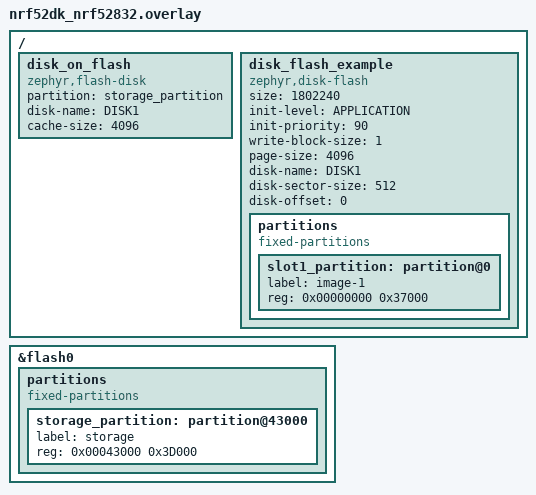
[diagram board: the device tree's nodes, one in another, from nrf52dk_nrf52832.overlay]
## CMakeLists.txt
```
# SPDX-License-Identifier: Apache-2.0

cmake_minimum_required(VERSION 3.20.0)
find_package(Zephyr REQUIRED HINTS $ENV{ZEPHYR_BASE})
project(flash_disk)

option(IMAGE_SECONDARY "Builds the secondary image" OFF)

zephyr_library_include_directories(${ZEPHYR_BASE}/drivers/flash)

if(IMAGE_SECONDARY)
FILE(GLOB app_sources src/secondary.c)
else()
FILE(GLOB app_sources src/main.c)
endif()

target_sources(app PRIVATE ${app_sources})

set(SECONDARY_IMAGE_HEX ${CMAKE_CURRENT_SOURCE_DIR}/generated/secondary.hex)
if(IMAGE_SECONDARY)
message("Secondary image")
set(ZEPHYR_OUTPUT_HEX ${CMAKE_CURRENT_BINARY_DIR}/zephyr/${KERNEL_HEX_NAME})
add_custom_command(
    COMMAND ${CMAKE_COMMAND} -E copy ${ZEPHYR_OUTPUT_HEX} ${SECONDARY_IMAGE_HEX}
    OUTPUT  ${SECONDARY_IMAGE_HEX}
    DEPENDS ${ZEPHYR_OUTPUT_HEX}
    COMMENT "Running post-build copying step..."
)
add_custom_target(
    post_bin ALL
    DEPENDS ${SECONDARY_IMAGE_HEX}
)
else()
set(gen_dir ${ZEPHYR_BINARY_DIR}/include/generated/)
generate_inc_file_for_target(app ${SECONDARY_IMAGE_HEX} ${gen_dir}/secondary.inc)
endif()
```

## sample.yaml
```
sample:
  name: Disk Flash Sample
tests:
  sample.drivers.flash_disk:
    tags:
    - flash
    filter: CONFIG_FLASH_HAS_DRIVER_ENABLED
    harness: console
    harness_config:
      type: one_line
      regex:
      - ".*Read/Write test successful"
```

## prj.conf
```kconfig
CONFIG_FLASH=y
CONFIG_MPU_ALLOW_FLASH_WRITE=y
CONFIG_MINIMAL_LIBC=y

# Enable flash on disk
CONFIG_FLASH_DRIVER_DISK=y

# Enable disk on flash
CONFIG_DISK_ACCESS=y
CONFIG_DISK_DRIVERS=y
#CONFIG_DISK_DRIVER_FLASH=y


# Logging
CONFIG_LOG=y
CONFIG_LOG_DEFAULT_LEVEL=4

# Config dfu
CONFIG_STREAM_FLASH=y
CONFIG_FLASH_MAP=y
CONFIG_IMG_MANAGER=y
CONFIG_MCUBOOT_IMG_MANAGER=y
CONFIG_IMG_ERASE_PROGRESSIVELY=y
CONFIG_REBOOT=y
CONFIG_BOOTLOADER_MCUBOOT=y
```

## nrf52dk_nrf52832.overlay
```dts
/*
 * Copyright (c) 2022-2023 Nordic Semiconductor ASA
 *
 * SPDX-License-Identifier: Apache-2.0
 */

/delete-node/ &slot1_partition;
/delete-node/ &storage_partition;

&flash0 {
	partitions {
		compatible = "fixed-partitions";
		#address-cells = <1>;
		#size-cells = <1>;

		storage_partition: partition@43000 {
			label = "storage";
			reg = <0x00043000 0x3D000>;
		};
	};
};
 
 ///delete-node/ &slot1_partition;
 
 / { 
	disk_on_flash: disk_on_flash {
		compatible = "zephyr,flash-disk";
		status = "okay";
		partition = < &storage_partition >;
		disk-name = "DISK1";
		cache-size = <4096>;
 	};
	disk_flash_example: disk_flash_example {
		compatible = "zephyr,disk-flash";
		status = "okay";
		size = <1802240>;
		init-level = "APPLICATION";
		init-priority = <90>;
		write-block-size = <1>;
		page-size = <4096>;
		disk-name = "DISK1";
		disk-sector-size = <512>;
		disk-offset = <0>;

		partitions {
			compatible = "fixed-partitions";
			#address-cells = <1>;
			#size-cells = <1>;

			slot1_partition: partition@0 {
				label = "image-1";
				reg = <0x00000000 0x37000>;
			};
		};
	};
};
```

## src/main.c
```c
/*
 * Copyright (c) 2023 Endress+Hauser AG
 *
 * SPDX-License-Identifier: Apache-2.0
 */

#include <zephyr/kernel.h>
#include <zephyr/device.h>
#include <zephyr/drivers/flash.h>
#include <zephyr/dfu/mcuboot.h>
#include <zephyr/dfu/flash_img.h>
#include <zephyr/logging/log.h>

// #if DT_HAS_COMPAT_STATUS_OKAY(zephyr_disk_flash)
// #define FLASH_NODE DT_COMPAT_GET_ANY_STATUS_OKAY(zephyr_disk_flash)
// #else
// #error Unsupported flash driver
// #define FLASH_NODE DT_INVALID_NODE
// #endif

LOG_MODULE_REGISTER(main, CONFIG_LOG_DEFAULT_LEVEL);

// static char const secondary[] = {
// #include "secondary.inc"
// };

int main(void)
{
	int res = -1;
	//const struct device *const slot1_dev = DEVICE_DT_GET(FLASH_NODE);
	//uint16_t const image_size = (uint16_t)sizeof(secondary);
	uint16_t bytes_written = 0;
	// k_msleep(3000);

	// if(!boot_is_img_confirmed()) {
	// 	LOG_INF("Confirming image");
	// } else {
	// 	LOG_INF("Image already confirmed");
	// }

	//LOG_INF("Secondary image starts with: %x", secondary[5]);
	// while(bytes_written < image_size) {
	// 	LOG_INF("Progress %d/%d", bytes_written, image_size);
	// 	res = flash_write(slot1_dev, bytes_written, &secondary[bytes_written], 50);
	// 	if(res != 0) {
	// 		LOG_ERR("Write not possible");
	// 		return -1;
	// 	}
	// 	bytes_written += 50;
	// }
	LOG_INF("Secondary image written successfully");

	// res = flash_img_init_id(&flash_context, DT_FIXED_PARTITION_ID(DT_NODELABEL(slot1_partition)));
	// if(res != 0) {
	// 	LOG_ERR("Flash image init not possible for id DT_FIXED_PARTITION_ID(DT_NODELABEL(slot1_partition))");
	// }

	// res = flash_img_buffered_write(&flash_context, secondary, sizeof(secondary), true);
	// if(res != 0) {
	// 	LOG_ERR("Flash image write not possible");
	// }

	// res =  boot_request_upgrade(BOOT_UPGRADE_TEST);
	// if(res != 0) {
	// 	LOG_ERR("Upgrade not possible");
	// }

	return 0;
}
```

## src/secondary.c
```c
/*
 * Copyright (c) 2023 Endress+Hauser AG
 *
 * SPDX-License-Identifier: Apache-2.0
 */

#include <zephyr/kernel.h>
#include <zephyr/device.h>
#include <zephyr/drivers/flash.h>
#include <zephyr/dfu/mcuboot.h>
#include <zephyr/logging/log.h>

#if DT_HAS_COMPAT_STATUS_OKAY(zephyr_disk_flash)
#define FLASH_NODE DT_COMPAT_GET_ANY_STATUS_OKAY(zephyr_disk_flash)
#else
#error Unsupported flash driver
#define FLASH_NODE DT_INVALID_NODE
#endif

LOG_MODULE_REGISTER(main, CONFIG_LOG_DEFAULT_LEVEL);

int main(void)
{
	int upgrade = -1;

	if(!boot_is_img_confirmed()) {
		LOG_INF("Confirming image");
	} else {
		LOG_INF("Image already confirmed");
	}

	LOG_INF("Upgrading to primary");
	upgrade =  boot_request_upgrade(BOOT_UPGRADE_TEST);
	if(upgrade != 0) {
		LOG_ERR("Upgrade not possible");
	}

	return 0;
}
```
